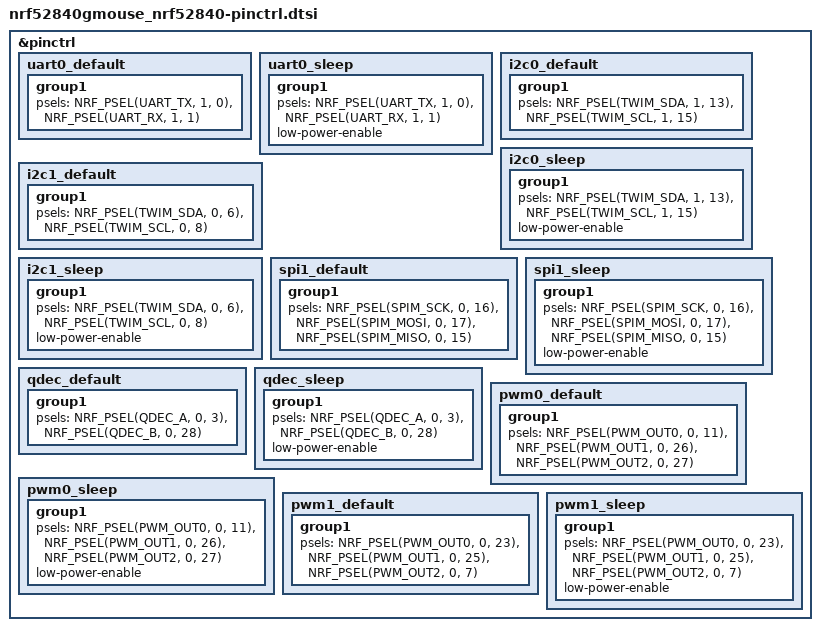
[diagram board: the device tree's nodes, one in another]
/*
 * Copyright (c) 2022 Nordic Semiconductor ASA
 *
 * SPDX-License-Identifier: LicenseRef-Nordic-5-Clause
 */

&pinctrl {
	uart0_default: uart0_default {
		group1 {
			psels = <NRF_PSEL(UART_TX, 1, 0)>,
				<NRF_PSEL(UART_RX, 1, 1)>;
		};
	};

	uart0_sleep: uart0_sleep {
		group1 {
			psels = <NRF_PSEL(UART_TX, 1, 0)>,
				<NRF_PSEL(UART_RX, 1, 1)>;
			low-power-enable;
		};
	};

	i2c0_default: i2c0_default {
		group1 {
			psels = <NRF_PSEL(TWIM_SDA, 1, 13)>,
				<NRF_PSEL(TWIM_SCL, 1, 15)>;
		};
	};

	i2c0_sleep: i2c0_sleep {
		group1 {
			psels = <NRF_PSEL(TWIM_SDA, 1, 13)>,
				<NRF_PSEL(TWIM_SCL, 1, 15)>;
			low-power-enable;
		};
	};

	i2c1_default: i2c1_default {
		group1 {
			psels = <NRF_PSEL(TWIM_SDA, 0, 6)>,
				<NRF_PSEL(TWIM_SCL, 0, 8)>;
		};
	};

	i2c1_sleep: i2c1_sleep {
		group1 {
			psels = <NRF_PSEL(TWIM_SDA, 0, 6)>,
				<NRF_PSEL(TWIM_SCL, 0, 8)>;
			low-power-enable;
		};
	};

	spi1_default: spi1_default {
		group1 {
			psels = <NRF_PSEL(SPIM_SCK, 0, 16)>,
				<NRF_PSEL(SPIM_MOSI, 0, 17)>,
				<NRF_PSEL(SPIM_MISO, 0, 15)>;
		};
	};

	spi1_sleep: spi1_sleep {
		group1 {
			psels = <NRF_PSEL(SPIM_SCK, 0, 16)>,
				<NRF_PSEL(SPIM_MOSI, 0, 17)>,
				<NRF_PSEL(SPIM_MISO, 0, 15)>;
			low-power-enable;
		};
	};

	qdec_default: qdec_default {
		group1 {
			psels = <NRF_PSEL(QDEC_A, 0, 3)>,
				<NRF_PSEL(QDEC_B, 0, 28)>;
		};
	};

	qdec_sleep: qdec_sleep {
		group1 {
			psels = <NRF_PSEL(QDEC_A, 0, 3)>,
				<NRF_PSEL(QDEC_B, 0, 28)>;
			low-power-enable;
		};
	};

	pwm0_default: pwm0_default {
		group1 {
			psels = <NRF_PSEL(PWM_OUT0, 0, 11)>,
				<NRF_PSEL(PWM_OUT1, 0, 26)>,
				<NRF_PSEL(PWM_OUT2, 0, 27)>;
		};
	};

	pwm0_sleep: pwm0_sleep {
		group1 {
			psels = <NRF_PSEL(PWM_OUT0, 0, 11)>,
				<NRF_PSEL(PWM_OUT1, 0, 26)>,
				<NRF_PSEL(PWM_OUT2, 0, 27)>;
			low-power-enable;
		};
	};

	pwm1_default: pwm1_default {
		group1 {
			psels = <NRF_PSEL(PWM_OUT0, 0, 23)>,
				<NRF_PSEL(PWM_OUT1, 0, 25)>,
				<NRF_PSEL(PWM_OUT2, 0, 7)>;
		};
	};

	pwm1_sleep: pwm1_sleep {
		group1 {
			psels = <NRF_PSEL(PWM_OUT0, 0, 23)>,
				<NRF_PSEL(PWM_OUT1, 0, 25)>,
				<NRF_PSEL(PWM_OUT2, 0, 7)>;
			low-power-enable;
		};
	};

};
